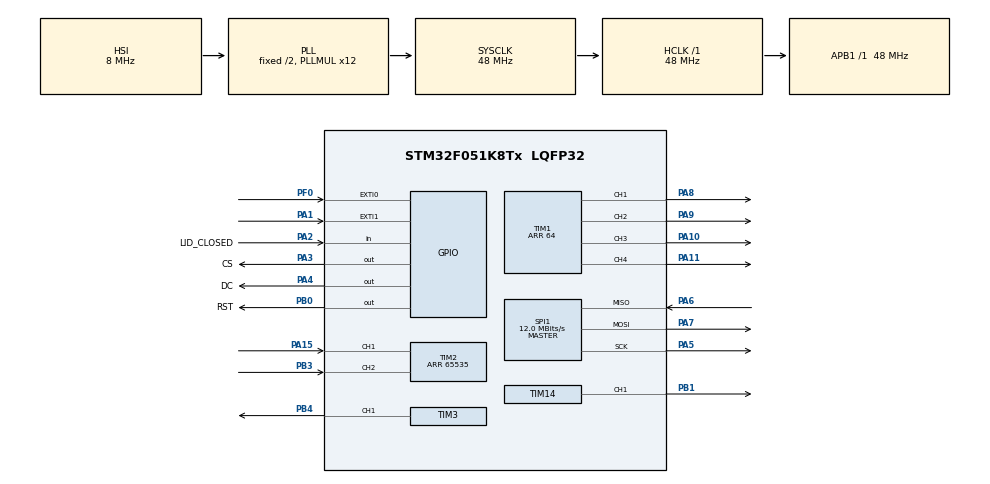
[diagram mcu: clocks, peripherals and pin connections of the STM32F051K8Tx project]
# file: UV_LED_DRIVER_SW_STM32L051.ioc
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Mcu.Family=STM32F0
Mcu.Name=STM32F051K8Tx
Mcu.Package=LQFP32
Mcu.UserConstants=MAX_ENCODER_LIMIT,680
NVIC.EXTI0_1_IRQn=true\:1\:0\:true\:false\:true\:true\:true
NVIC.TIM2_IRQn=true\:1\:0\:true\:false\:true\:true\:true
NVIC.TIM6_DAC_IRQn=true\:1\:0\:true\:false\:true\:true\:true
PA1.GPIO_PuPd=GPIO_PULLDOWN
PA1.Signal=GPXTI1
PA10.Signal=S_TIM1_CH3
PA11.Signal=S_TIM1_CH4
PA13.Mode=Serial_Wire
PA13.Signal=SYS_SWDIO
PA14.Mode=Serial_Wire
PA14.Signal=SYS_SWCLK
PA15.Signal=S_TIM2_CH1_ETR
PA2.GPIO_Label=LID_CLOSED
PA2.GPIO_PuPd=GPIO_PULLDOWN
PA2.Signal=GPIO_Input
PA3.GPIO_Label=CS
PA3.Signal=GPIO_Output
PA4.GPIO_Label=DC
PA4.Signal=GPIO_Output
PA5.Mode=Full_Duplex_Master
PA5.Signal=SPI1_SCK
PA6.Mode=Full_Duplex_Master
PA6.Signal=SPI1_MISO
PA7.Mode=Full_Duplex_Master
PA7.Signal=SPI1_MOSI
PA8.Signal=S_TIM1_CH1
PA9.Signal=S_TIM1_CH2
PB0.GPIO_Label=RST
PB0.Signal=GPIO_Output
PB1.Signal=S_TIM14_CH1
PB3.Signal=S_TIM2_CH2
PB4.GPIO_PuPd=GPIO_PULLDOWN
PB4.Signal=S_TIM3_CH1
PF0-OSC_IN.GPIO_PuPd=GPIO_PULLDOWN
PF0-OSC_IN.Signal=GPXTI0
ProjectManager.HeapSize=0x200
ProjectManager.StackSize=0x400
ProjectManager.TargetToolchain=STM32CubeIDE
RCC.AHBFreq_Value=48000000
RCC.APB1Freq_Value=48000000
RCC.APB1TimFreq_Value=48000000
RCC.HCLKFreq_Value=48000000
RCC.PLLMUL=RCC_PLL_MUL12
RCC.SYSCLKFreq_VALUE=48000000
RCC.SYSCLKSource=RCC_SYSCLKSOURCE_PLLCLK
SH.S_TIM14_CH1.0=TIM14_CH1,PWM Generation1 CH1
SH.S_TIM1_CH1.0=TIM1_CH1,PWM Generation1 CH1
SH.S_TIM1_CH2.0=TIM1_CH2,PWM Generation2 CH2
SH.S_TIM1_CH3.0=TIM1_CH3,PWM Generation3 CH3
SH.S_TIM1_CH4.0=TIM1_CH4,PWM Generation4 CH4
SH.S_TIM2_CH1_ETR.0=TIM2_CH1,Encoder_Interface
SH.S_TIM2_CH2.0=TIM2_CH2,Encoder_Interface
SH.S_TIM3_CH1.0=TIM3_CH1,PWM Generation1 CH1
SPI1.BaudRatePrescaler=SPI_BAUDRATEPRESCALER_4
SPI1.CalculateBaudRate=12.0 MBits/s
SPI1.DataSize=SPI_DATASIZE_8BIT
SPI1.Direction=SPI_DIRECTION_2LINES
SPI1.Mode=SPI_MODE_MASTER
SPI1.VirtualType=VM_MASTER
TIM1.Channel-PWM\ Generation1\ CH1=TIM_CHANNEL_1
TIM1.Channel-PWM\ Generation2\ CH2=TIM_CHANNEL_2
TIM1.Channel-PWM\ Generation3\ CH3=TIM_CHANNEL_3
TIM1.Channel-PWM\ Generation4\ CH4=TIM_CHANNEL_4
TIM1.Period=64
TIM14.Channel=TIM_CHANNEL_1
TIM14.Period=64
TIM17.Period=65535
TIM17.Prescaler=65535
TIM2.AutoReloadPreload=TIM_AUTORELOAD_PRELOAD_ENABLE
TIM2.CounterMode=TIM_COUNTERMODE_CENTERALIGNED2
TIM2.EncoderMode=TIM_ENCODERMODE_TI12
TIM2.IC1Filter=4
TIM2.IC2Filter=4
TIM2.Period=65535
TIM2.TIM_MasterOutputTrigger=TIM_TRGO_UPDATE
TIM3.Channel-PWM\ Generation1\ CH1=TIM_CHANNEL_1
TIM3.Period=1
TIM6.AutoReloadPreload=TIM_AUTORELOAD_PRELOAD_ENABLE
TIM6.Period=65535
TIM6.Prescaler=704
VP_TIM14_VS_ClockSourceINT.Mode=Enable_Timer
VP_TIM16_VS_ClockSourceINT.Mode=Enable_Timer
VP_TIM17_VS_ClockSourceINT.Mode=Enable_Timer
VP_TIM6_VS_ClockSourceINT.Mode=Enable_Timer
board=custom

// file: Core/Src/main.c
/* USER CODE BEGIN Header */
/**
  ******************************************************************************
  * @file           : main.c
  * @brief          : Main program body
  ******************************************************************************
  * @attention
  *
  * <h2><center>&copy; Copyright (c) 2020 STMicroelectronics.
  * All rights reserved.</center></h2>
  *
  * This software component is licensed by ST under BSD 3-Clause license,
  * the "License"; You may not use this file except in compliance with the
  * License. You may obtain a copy of the License at:
  *                        opensource.org/licenses/BSD-3-Clause
  *
  ******************************************************************************
  */
/* USER CODE END Header */

#include "main.h"
#include "spi.h"
#include "tim.h"
#include "gpio.h"

/* USER CODE BEGIN Includes */
#include "UvboxManager.h"
#include "LedManager.h"

/* USER CODE END Includes */

/* USER CODE BEGIN PV */

// default lid status

/* USER CODE END PV */

void SystemClock_Config(void);

int main(void)
{

  /* MCU Configuration--------------------------------------------------------*/

  /* Reset of all peripherals, Initializes the Flash interface and the Systick. */
  HAL_Init();

  /* Configure the system clock */
  SystemClock_Config();

  /* Initialize all configured peripherals */
  MX_GPIO_Init();
  MX_TIM1_Init();
  MX_TIM17_Init();
  MX_TIM14_Init();
  MX_SPI1_Init();
  MX_TIM2_Init();
  MX_TIM3_Init();
  MX_TIM16_Init();
  MX_TIM6_Init();
  /* USER CODE BEGIN 2 */

  UM_Setup();

  /* USER CODE END 2 */

  /* Infinite loop */
  /* USER CODE BEGIN WHILE */
  while (1)
  {

	 // LM_UpdatePwm();
	  UM_UpdateDisplay();
		// monitor the lid gpio - PA2 - if lid is held closed
		if(HAL_GPIO_ReadPin(LID_CLOSED_GPIO_Port, LID_CLOSED_Pin) == GPIO_PIN_SET)
		{
			// if timer_expired_state == false
			if(EM_getSystemState() != UVBOX_TimerExpired)
				EM_ProcessEvent(UVBOX_evStartTimer);
		}
		else
		{
			// Timer is only reset if you lift the lid
			EM_ProcessEvent(UVBOX_evResetTimer);
		}

    /* USER CODE END WHILE */

  }
}

void SystemClock_Config(void)
{
  RCC_OscInitTypeDef RCC_OscInitStruct = {0};
  RCC_ClkInitTypeDef RCC_ClkInitStruct = {0};

  /** Initializes the CPU, AHB and APB busses clocks
  */
  RCC_OscInitStruct.OscillatorType = RCC_OSCILLATORTYPE_HSI;
  RCC_OscInitStruct.HSIState = RCC_HSI_ON;
  RCC_OscInitStruct.HSICalibrationValue = RCC_HSICALIBRATION_DEFAULT;
  RCC_OscInitStruct.PLL.PLLState = RCC_PLL_ON;
  RCC_OscInitStruct.PLL.PLLSource = RCC_PLLSOURCE_HSI;
  RCC_OscInitStruct.PLL.PLLMUL = RCC_PLL_MUL12;
  RCC_OscInitStruct.PLL.PREDIV = RCC_PREDIV_DIV1;
  if (HAL_RCC_OscConfig(&RCC_OscInitStruct) != HAL_OK)
  {
    Error_Handler();
  }
  /** Initializes the CPU, AHB and APB busses clocks
  */
  RCC_ClkInitStruct.ClockType = RCC_CLOCKTYPE_HCLK|RCC_CLOCKTYPE_SYSCLK
                              |RCC_CLOCKTYPE_PCLK1;
  RCC_ClkInitStruct.SYSCLKSource = RCC_SYSCLKSOURCE_PLLCLK;
  RCC_ClkInitStruct.AHBCLKDivider = RCC_SYSCLK_DIV1;
  RCC_ClkInitStruct.APB1CLKDivider = RCC_HCLK_DIV1;

  if (HAL_RCC_ClockConfig(&RCC_ClkInitStruct, FLASH_LATENCY_1) != HAL_OK)
  {
    Error_Handler();
  }
}

void Error_Handler(void)
{
}

/************************ (C) COPYRIGHT STMicroelectronics *****END OF FILE****/
